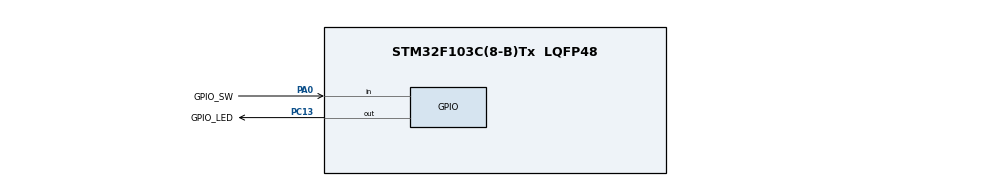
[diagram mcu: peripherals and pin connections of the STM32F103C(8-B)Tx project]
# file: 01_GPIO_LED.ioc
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Mcu.Family=STM32F1
Mcu.Name=STM32F103C(8-B)Tx
Mcu.Package=LQFP48
NVIC.PriorityGroup=NVIC_PRIORITYGROUP_4
PA0-WKUP.GPIO_Label=GPIO_SW
PA0-WKUP.GPIO_PuPd=GPIO_PULLUP
PA0-WKUP.Signal=GPIO_Input
PA13.Mode=Serial_Wire
PA13.Signal=SYS_JTMS-SWDIO
PA14.Mode=Serial_Wire
PA14.Signal=SYS_JTCK-SWCLK
PC13-TAMPER-RTC.GPIO_Label=GPIO_LED
PC13-TAMPER-RTC.GPIO_PuPd=GPIO_PULLDOWN
PC13-TAMPER-RTC.GPIO_Speed=GPIO_SPEED_FREQ_HIGH
PC13-TAMPER-RTC.PinState=GPIO_PIN_SET
PC13-TAMPER-RTC.Signal=GPIO_Output
ProjectManager.HeapSize=0x200
ProjectManager.StackSize=0x400
ProjectManager.TargetToolchain=STM32CubeIDE
RCC.APB1Freq_Value=8000000
RCC.APB2Freq_Value=8000000
board=custom

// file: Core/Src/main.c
/* USER CODE BEGIN Header */
/**
  ******************************************************************************
  * @file           : main.c
  * @brief          : Main program body
  ******************************************************************************
  * @attention
  *
  * Copyright (c) 2026 STMicroelectronics.
  * All rights reserved.
  *
  * This software is licensed under terms that can be found in the LICENSE file
  * in the root directory of this software component.
  * If no LICENSE file comes with this software, it is provided AS-IS.
  *
  ******************************************************************************
  */
/* USER CODE END Header */
#include "main.h"

void SystemClock_Config(void);
static void MX_GPIO_Init(void);

int main(void)
{

  /* MCU Configuration--------------------------------------------------------*/

  /* Reset of all peripherals, Initializes the Flash interface and the Systick. */
  HAL_Init();

  /* Configure the system clock */
  SystemClock_Config();

  /* Initialize all configured peripherals */
  //MX_GPIO_Init();
  /* USER CODE BEGIN 2 */

  volatile unsigned int * reg = (volatile unsigned int *)0x40021018; // *(0x40021018) |= 16 == __HAL_RCC_GPIOC_CLK_ENABLE()
  *reg |= 16; // clock 설정. D2 LED 제어를 위해 필요한 PC13 제어를 위한 GPIOC CLK를 Enable

  // MX_GPIO_Init의 Configure GPIO pin Output Level 부분
  /*
  GPIO_InitTypeDef GPIO_InitStruct = {0};
  GPIO_InitStruct.Pin = GPIO_LED_Pin;
  GPIO_InitStruct.Mode = GPIO_MODE_OUTPUT_PP;
  GPIO_InitStruct.Pull = GPIO_PULLUP;
  GPIO_InitStruct.Speed = GPIO_SPEED_FREQ_HIGH;
  HAL_GPIO_Init(GPIO_LED_GPIO_Port, &GPIO_InitStruct);
  */

  volatile unsigned int * reg2 = (volatile unsigned int *)0x40011004;
  *reg2 = (*reg2 & ~(15UL << 20U)) | (3U << 20U);

  /* USER CODE END 2 */

  /* Infinite loop */
  /* USER CODE BEGIN WHILE */
  volatile unsigned int * reg3 = (volatile unsigned int *)0x40011010;
  while (1)
  {
	  *reg3 = 0x2000;	// HEX, 10진수로 8192. GPIOC를 High 만듦
	  // == HAL_GPIO_WritePin(GPIO_LED_GPIO_Port, GPIO_LED_Pin, GPIO_PIN_SET)
	  HAL_Delay(1000);

	  *reg3 = (0x2000 << 16);	// GPIOC를 Low로 떨어뜨림
	  HAL_Delay(1000);

	  /* HAL_GPIO_WritePin(GPIO_LED_GPIO_Port, GPIO_LED_Pin, 1);
	  HAL_Delay(100);
	  HAL_GPIO_WritePin(GPIO_LED_GPIO_Port, GPIO_LED_Pin, 0);
	  HAL_Delay(100);

	  if(!HAL_GPIO_ReadPin(GPIO_SW_GPIO_Port, GPIO_SW_Pin)){
		  HAL_GPIO_WritePin(GPIO_LED_GPIO_Port, GPIO_LED_Pin, 0);
	  }else{
		  HAL_GPIO_WritePin(GPIO_LED_GPIO_Port, GPIO_LED_Pin, 1);
	  }

	  HAL_Delay(100);  */

    /* USER CODE END WHILE */

  }
}

void SystemClock_Config(void)
{
  RCC_OscInitTypeDef RCC_OscInitStruct = {0};
  RCC_ClkInitTypeDef RCC_ClkInitStruct = {0};

  /** Initializes the RCC Oscillators according to the specified parameters
  * in the RCC_OscInitTypeDef structure.
  */
  RCC_OscInitStruct.OscillatorType = RCC_OSCILLATORTYPE_HSI;
  RCC_OscInitStruct.HSIState = RCC_HSI_ON;
  RCC_OscInitStruct.HSICalibrationValue = RCC_HSICALIBRATION_DEFAULT;
  RCC_OscInitStruct.PLL.PLLState = RCC_PLL_NONE;
  if (HAL_RCC_OscConfig(&RCC_OscInitStruct) != HAL_OK)
  {
    Error_Handler();
  }

  /** Initializes the CPU, AHB and APB buses clocks
  */
  RCC_ClkInitStruct.ClockType = RCC_CLOCKTYPE_HCLK|RCC_CLOCKTYPE_SYSCLK
                              |RCC_CLOCKTYPE_PCLK1|RCC_CLOCKTYPE_PCLK2;
  RCC_ClkInitStruct.SYSCLKSource = RCC_SYSCLKSOURCE_HSI;
  RCC_ClkInitStruct.AHBCLKDivider = RCC_SYSCLK_DIV1;
  RCC_ClkInitStruct.APB1CLKDivider = RCC_HCLK_DIV1;
  RCC_ClkInitStruct.APB2CLKDivider = RCC_HCLK_DIV1;

  if (HAL_RCC_ClockConfig(&RCC_ClkInitStruct, FLASH_LATENCY_0) != HAL_OK)
  {
    Error_Handler();
  }
}

static void MX_GPIO_Init(void)
{
  GPIO_InitTypeDef GPIO_InitStruct = {0};

  /* GPIO Ports Clock Enable */
  __HAL_RCC_GPIOC_CLK_ENABLE(); //*(0x40021018) |= 16
  __HAL_RCC_GPIOA_CLK_ENABLE();

  /*Configure GPIO pin Output Level */
  HAL_GPIO_WritePin(GPIO_LED_GPIO_Port, GPIO_LED_Pin, GPIO_PIN_SET);

  /*Configure GPIO pin : GPIO_LED_Pin */
  GPIO_InitStruct.Pin = GPIO_LED_Pin;
  GPIO_InitStruct.Mode = GPIO_MODE_OUTPUT_PP;
  GPIO_InitStruct.Pull = GPIO_PULLDOWN;
  GPIO_InitStruct.Speed = GPIO_SPEED_FREQ_HIGH;
  HAL_GPIO_Init(GPIO_LED_GPIO_Port, &GPIO_InitStruct);

  /*Configure GPIO pin : GPIO_SW_Pin */
  GPIO_InitStruct.Pin = GPIO_SW_Pin;
  GPIO_InitStruct.Mode = GPIO_MODE_INPUT;
  GPIO_InitStruct.Pull = GPIO_PULLUP;
  HAL_GPIO_Init(GPIO_SW_GPIO_Port, &GPIO_InitStruct);

}

void Error_Handler(void)
{
  __disable_irq();
  while (1)
  {
  }
}
